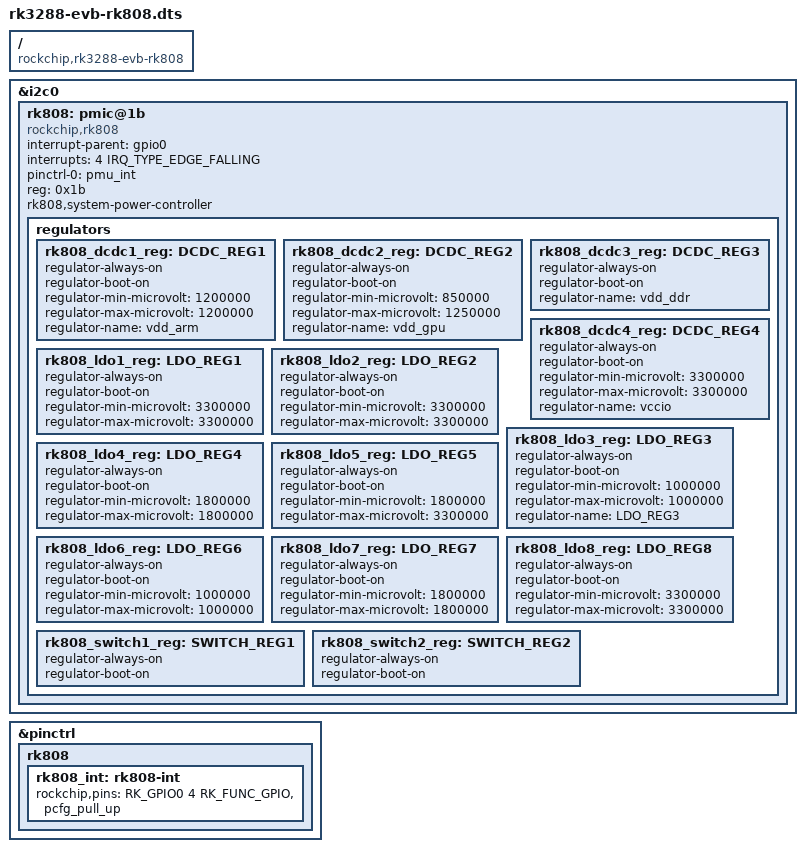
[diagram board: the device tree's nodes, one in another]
/*
 * This program is free software; you can redistribute it and/or modify
 * it under the terms of the GNU General Public License as published by
 * the Free Software Foundation; either version 2 of the License, or
 * (at your option) any later version.
 *
 * This program is distributed in the hope that it will be useful,
 * but WITHOUT ANY WARRANTY; without even the implied warranty of
 * MERCHANTABILITY or FITNESS FOR A PARTICULAR PURPOSE.  See the
 * GNU General Public License for more details.
 */

/dts-v1/;
#include "rk3288-evb.dtsi"

/ {
	compatible = "rockchip,rk3288-evb-rk808", "rockchip,rk3288";
};

&i2c0 {
	status = "okay";

	rk808: pmic@1b {
		compatible = "rockchip,rk808";
		interrupt-parent = <&gpio0>;
		interrupts = <4 IRQ_TYPE_EDGE_FALLING>;
		pinctrl-names = "default";
		pinctrl-0 = <&pmu_int>;
		reg = <0x1b>;
		rk808,system-power-controller;

		regulators {
			rk808_dcdc1_reg: DCDC_REG1 {
				regulator-always-on;
				regulator-boot-on;
				regulator-min-microvolt = <1200000>;
				regulator-max-microvolt = <1200000>;
				regulator-name = "vdd_arm";
			};

			rk808_dcdc2_reg: DCDC_REG2 {
				regulator-always-on;
				regulator-boot-on;
				regulator-min-microvolt = <850000>;
				regulator-max-microvolt = <1250000>;
				regulator-name = "vdd_gpu";
			};

			rk808_dcdc3_reg: DCDC_REG3 {
				regulator-always-on;
				regulator-boot-on;
				regulator-name = "vdd_ddr";
			};

			rk808_dcdc4_reg: DCDC_REG4 {
				regulator-always-on;
				regulator-boot-on;
				regulator-min-microvolt = <3300000>;
				regulator-max-microvolt = <3300000>;
				regulator-name = "vccio";
			};

			rk808_ldo1_reg: LDO_REG1 {
				regulator-always-on;
				regulator-boot-on;
				regulator-min-microvolt = <3300000>;
				regulator-max-microvolt = <3300000>;
			};

			rk808_ldo2_reg: LDO_REG2 {
				regulator-always-on;
				regulator-boot-on;
				regulator-min-microvolt = <3300000>;
				regulator-max-microvolt = <3300000>;
			};

			rk808_ldo3_reg: LDO_REG3 {
				regulator-always-on;
				regulator-boot-on;
				regulator-min-microvolt = <1000000>;
				regulator-max-microvolt = <1000000>;
				regulator-name = "LDO_REG3";
			};

			rk808_ldo4_reg: LDO_REG4 {
				regulator-always-on;
				regulator-boot-on;
				regulator-min-microvolt = <1800000>;
				regulator-max-microvolt = <1800000>;
			};

			rk808_ldo5_reg: LDO_REG5 {
				regulator-always-on;
				regulator-boot-on;
				regulator-min-microvolt = <1800000>;
				regulator-max-microvolt = <3300000>;
			};

			rk808_ldo6_reg: LDO_REG6 {
				regulator-always-on;
				regulator-boot-on;
				regulator-min-microvolt = <1000000>;
				regulator-max-microvolt = <1000000>;
			};

			rk808_ldo7_reg: LDO_REG7 {
				regulator-always-on;
				regulator-boot-on;
				regulator-min-microvolt = <1800000>;
				regulator-max-microvolt = <1800000>;
			};

			rk808_ldo8_reg: LDO_REG8 {
				regulator-always-on;
				regulator-boot-on;
				regulator-min-microvolt = <3300000>;
				regulator-max-microvolt = <3300000>;
			};

			rk808_switch1_reg: SWITCH_REG1 {
				regulator-always-on;
				regulator-boot-on;
			};

			rk808_switch2_reg: SWITCH_REG2 {
				regulator-always-on;
				regulator-boot-on;
			};
		};
	};
};

&pinctrl {
	rk808 {
		rk808_int: rk808-int {
			rockchip,pins = <RK_GPIO0 4 RK_FUNC_GPIO &pcfg_pull_up>;
		};
	};
};
